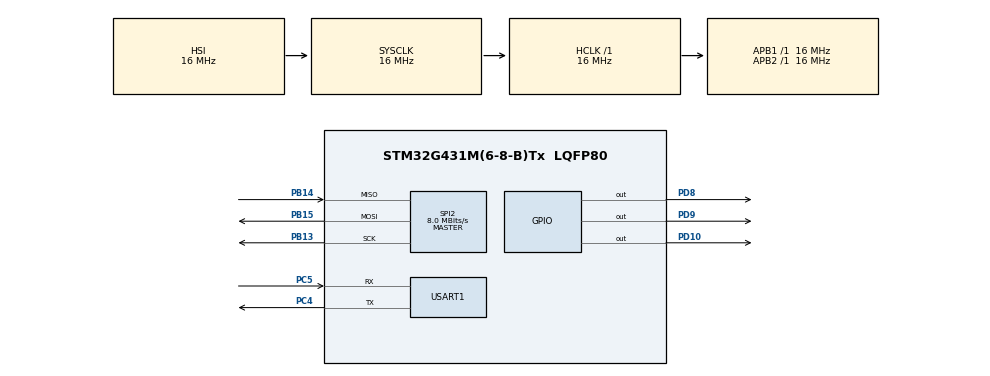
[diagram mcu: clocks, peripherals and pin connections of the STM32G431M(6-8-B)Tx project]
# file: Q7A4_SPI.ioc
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Mcu.Family=STM32G4
Mcu.Name=STM32G431M(6-8-B)Tx
Mcu.Package=LQFP80
NVIC.PriorityGroup=NVIC_PRIORITYGROUP_4
PA13.Mode=Serial_Wire
PA13.Signal=SYS_JTMS-SWDIO
PA14.Mode=Serial_Wire
PA14.Signal=SYS_JTCK-SWCLK
PB13.Mode=Full_Duplex_Master
PB13.Signal=SPI2_SCK
PB14.Mode=Full_Duplex_Master
PB14.Signal=SPI2_MISO
PB15.Mode=Full_Duplex_Master
PB15.Signal=SPI2_MOSI
PC4.Mode=Asynchronous
PC4.Signal=USART1_TX
PC5.Mode=Asynchronous
PC5.Signal=USART1_RX
PD10.Signal=GPIO_Output
PD8.Signal=GPIO_Output
PD9.Signal=GPIO_Output
ProjectManager.HeapSize=0x200
ProjectManager.StackSize=0x400
ProjectManager.TargetToolchain=STM32CubeIDE
RCC.AHBFreq_Value=16000000
RCC.APB1Freq_Value=16000000
RCC.APB1TimFreq_Value=16000000
RCC.APB2Freq_Value=16000000
RCC.APB2TimFreq_Value=16000000
RCC.CortexFreq_Value=16000000
RCC.EXTERNAL_CLOCK_VALUE=12288000
RCC.HCLKFreq_Value=16000000
RCC.HSE_VALUE=8000000
RCC.HSI48_VALUE=48000000
RCC.HSI_VALUE=16000000
RCC.LSE_VALUE=32768
RCC.SYSCLKFreq_VALUE=16000000
RCC.USBFreq_Value=64000000
RCC.VCOOutputFreq_Value=128000000
SPI2.CalculateBaudRate=8.0 MBits/s
SPI2.DataSize=SPI_DATASIZE_8BIT
SPI2.Direction=SPI_DIRECTION_2LINES
SPI2.Mode=SPI_MODE_MASTER
SPI2.VirtualType=VM_MASTER
USART1.VirtualMode-Asynchronous=VM_ASYNC
VP_SYS_VS_DBSignals.Mode=DisableDeadBatterySignals
board=custom

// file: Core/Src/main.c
/* USER CODE BEGIN Header */
/**
  ******************************************************************************
  * @file           : main.c
  * @brief          : Main program body
  ******************************************************************************
  * @attention
  *
  * Copyright (c) 2025 STMicroelectronics.
  * All rights reserved.
  *
  * This software is licensed under terms that can be found in the LICENSE file
  * in the root directory of this software component.
  * If no LICENSE file comes with this software, it is provided AS-IS.
  *
  ******************************************************************************
  */
/* USER CODE END Header */
#include "main.h"
#include "string.h"
#include "stdio.h"

/* USER CODE BEGIN Includes */
#define EEPROM_WREN  0x06 // Write Enable
#define EEPROM_WRITE 0x02 // Write Data
#define EEPROM_RDSR  0x05 // Read Status Register
#define EEPROM_READ  0x03 // Read Data
/* USER CODE END Includes */

SPI_HandleTypeDef hspi2;

UART_HandleTypeDef huart1;

void SystemClock_Config(void);
static void MX_GPIO_Init(void);
static void MX_SPI2_Init(void);
static void MX_USART1_UART_Init(void);

#include "main.h"
#include "string.h"
#include "stdio.h"

/* USER CODE BEGIN Includes */
#define EEPROM_WREN  0x06 // Write Enable
#define EEPROM_WRITE 0x02 // Write Data
#define EEPROM_RDSR  0x05 // Read Status Register
#define EEPROM_READ  0x03 // Read Data
/* USER CODE END Includes */

SPI_HandleTypeDef hspi2;

UART_HandleTypeDef huart1;

void SystemClock_Config(void);
static void MX_GPIO_Init(void);
static void MX_SPI2_Init(void);
static void MX_USART1_UART_Init(void);

int main(void)
{
  /* USER CODE BEGIN 1 */
  HAL_StatusTypeDef status;
  /* USER CODE END 1 */

  /* MCU Configuration--------------------------------------------------------*/

  /* Reset of all peripherals, Initializes the Flash interface and the Systick. */
  HAL_Init();

  /* Configure the system clock */
  SystemClock_Config();

  /* USER CODE BEGIN SysInit */
  // MX_IWDG_Init(); // Disabled to prevent resets
  /* USER CODE END SysInit */

  /* Initialize all configured peripherals */
  MX_GPIO_Init();
  MX_SPI2_Init();
  MX_USART1_UART_Init();
  /* USER CODE BEGIN 2 */
  uint8_t addr[2];
  uint16_t memAddr = 0x100; // EEPROM address
  uint8_t DATA_TO_SPI[8] = {'C', '-', 'D', 'A', 'C', 'B', 'L', 'R'}; // String to write
  uint8_t wip;
  uint8_t spiDataRecv[9]; // 8 bytes + null terminator
  char printBuffer[64];
  uint8_t wren_cmd = EEPROM_WREN;
  uint8_t write_cmd = EEPROM_WRITE;
  uint8_t rdsr_cmd = EEPROM_RDSR;
  uint8_t read_cmd = EEPROM_READ;

  HAL_GPIO_WritePin(GPIOD, GPIO_PIN_9, 1);
  HAL_GPIO_WritePin(GPIOD, GPIO_PIN_10, 1);
  HAL_GPIO_WritePin(GPIOD, GPIO_PIN_8, 1);
  HAL_Delay(500);

  // Send Write Enable command
  HAL_GPIO_WritePin(GPIOD, GPIO_PIN_8, 0);
  status = HAL_SPI_Transmit(&hspi2, (uint8_t*)&wren_cmd, 1, 1000);
  HAL_GPIO_WritePin(GPIOD, GPIO_PIN_8, 1);
  if (status != HAL_OK) {
    HAL_UART_Transmit(&huart1, (const uint8_t*)"Write Enable Failed\n\r", sizeof("Write Enable Failed\n\r"), 1000);
    while (1); // Halt on error
  }
  HAL_UART_Transmit(&huart1, (const uint8_t*)"Write Enabled\n\r", sizeof("Write Enabled\n\r"), 1000);

  // Prepare address
  addr[0] = memAddr >> 8; // High byte
  addr[1] = memAddr;      // Low byte

  // Write data to EEPROM
  HAL_GPIO_WritePin(GPIOD, GPIO_PIN_8, 0);
  status = HAL_SPI_Transmit(&hspi2, (uint8_t*)&write_cmd, 1, 1000);
  if (status == HAL_OK) {
    status = HAL_SPI_Transmit(&hspi2, (uint8_t*)addr, 2, 1000);
  }
  if (status == HAL_OK) {
    status = HAL_SPI_Transmit(&hspi2, (uint8_t*)DATA_TO_SPI, 8, 1000);
  }
  HAL_GPIO_WritePin(GPIOD, GPIO_PIN_8, 1);
  if (status != HAL_OK) {
    HAL_UART_Transmit(&huart1, (const uint8_t*)"Write Failed\n\r", sizeof("Write Failed\n\r"), 1000);
    while (1); // Halt on error
  }
  HAL_UART_Transmit(&huart1, (const uint8_t*)"Written\n\r", sizeof("Written\n\r"), 1000);

  // Poll Write-in-Progress
  wip = 1;
  while (wip)
  {
    HAL_GPIO_WritePin(GPIOD, GPIO_PIN_8, 0);
    status = HAL_SPI_Transmit(&hspi2, (uint8_t*)&rdsr_cmd, 1, 1000);
    if (status == HAL_OK) {
      status = HAL_SPI_Receive(&hspi2, (uint8_t*)&spiDataRecv, 1, 1000);
    }
    HAL_GPIO_WritePin(GPIOD, GPIO_PIN_8, 1);
    if (status != HAL_OK) {
      HAL_UART_Transmit(&huart1, (const uint8_t*)"Status Read Failed\n\r", sizeof("Status Read Failed\n\r"), 1000);
      while (1); // Halt on error
    }
    wip = spiDataRecv[0] & 0x01;
  }

  // Read data from EEPROM
  memset(spiDataRecv, 0, sizeof(spiDataRecv));
  HAL_GPIO_WritePin(GPIOD, GPIO_PIN_8, 0);
  status = HAL_SPI_Transmit(&hspi2, (uint8_t*)&read_cmd, 1, 1000);
  if (status == HAL_OK) {
    status = HAL_SPI_Transmit(&hspi2, (uint8_t*)addr, 2, 1000);
  }
  if (status == HAL_OK) {
    status = HAL_SPI_Receive(&hspi2, (uint8_t*)&spiDataRecv, 8, 1000);
  }
  HAL_GPIO_WritePin(GPIOD, GPIO_PIN_8, 1);
  if (status != HAL_OK) {
    HAL_UART_Transmit(&huart1, (const uint8_t*)"Read Failed\n\r", sizeof("Read Failed\n\r"), 1000);
    while (1); // Halt on error
  }

  spiDataRecv[8] = '\0'; // Null-terminate for string display
  sprintf(printBuffer, "\n\rData Received From addr: 0X%04X is: %s\n\r", memAddr, spiDataRecv);
  HAL_UART_Transmit(&huart1, (uint8_t*)printBuffer, strlen(printBuffer), 1000);

  memset(printBuffer, 0, sizeof(printBuffer));
  memset(spiDataRecv, 0, sizeof(spiDataRecv));
  /* USER CODE END 3 */
  while (1)
  {
    /* Infinite loop to prevent reset */
  }
}

void SystemClock_Config(void)
{
  RCC_OscInitTypeDef RCC_OscInitStruct = {0};
  RCC_ClkInitTypeDef RCC_ClkInitStruct = {0};

  /** Configure the main internal regulator output voltage
  */
  HAL_PWREx_ControlVoltageScaling(PWR_REGULATOR_VOLTAGE_SCALE1);

  /** Initializes the RCC Oscillators according to the specified parameters
  * in the RCC_OscInitTypeDef structure.
  */
  RCC_OscInitStruct.OscillatorType = RCC_OSCILLATORTYPE_HSI;
  RCC_OscInitStruct.HSIState = RCC_HSI_ON;
  RCC_OscInitStruct.HSICalibrationValue = RCC_HSICALIBRATION_DEFAULT;
  RCC_OscInitStruct.PLL.PLLState = RCC_PLL_NONE;
  if (HAL_RCC_OscConfig(&RCC_OscInitStruct) != HAL_OK)
  {
    Error_Handler();
  }

  /** Initializes the CPU, AHB and APB buses clocks
  */
  RCC_ClkInitStruct.ClockType = RCC_CLOCKTYPE_HCLK|RCC_CLOCKTYPE_SYSCLK
                              |RCC_CLOCKTYPE_PCLK1|RCC_CLOCKTYPE_PCLK2;
  RCC_ClkInitStruct.SYSCLKSource = RCC_SYSCLKSOURCE_HSI;
  RCC_ClkInitStruct.AHBCLKDivider = RCC_SYSCLK_DIV1;
  RCC_ClkInitStruct.APB1CLKDivider = RCC_HCLK_DIV1;
  RCC_ClkInitStruct.APB2CLKDivider = RCC_HCLK_DIV1;

  if (HAL_RCC_ClockConfig(&RCC_ClkInitStruct, FLASH_LATENCY_0) != HAL_OK)
  {
    Error_Handler();
  }
}

static void MX_SPI2_Init(void)
{

  /* SPI2 parameter configuration*/
  hspi2.Instance = SPI2;
  hspi2.Init.Mode = SPI_MODE_MASTER;
  hspi2.Init.Direction = SPI_DIRECTION_2LINES;
  hspi2.Init.DataSize = SPI_DATASIZE_8BIT;
  hspi2.Init.CLKPolarity = SPI_POLARITY_LOW;
  hspi2.Init.CLKPhase = SPI_PHASE_1EDGE;
  hspi2.Init.NSS = SPI_NSS_SOFT;
  hspi2.Init.BaudRatePrescaler = SPI_BAUDRATEPRESCALER_2;
  hspi2.Init.FirstBit = SPI_FIRSTBIT_MSB;
  hspi2.Init.TIMode = SPI_TIMODE_DISABLE;
  hspi2.Init.CRCCalculation = SPI_CRCCALCULATION_DISABLE;
  hspi2.Init.CRCPolynomial = 7;
  hspi2.Init.CRCLength = SPI_CRC_LENGTH_DATASIZE;
  hspi2.Init.NSSPMode = SPI_NSS_PULSE_ENABLE;
  if (HAL_SPI_Init(&hspi2) != HAL_OK)
  {
    Error_Handler();
  }

}

static void MX_USART1_UART_Init(void)
{

  huart1.Instance = USART1;
  huart1.Init.BaudRate = 115200;
  huart1.Init.WordLength = UART_WORDLENGTH_8B;
  huart1.Init.StopBits = UART_STOPBITS_1;
  huart1.Init.Parity = UART_PARITY_NONE;
  huart1.Init.Mode = UART_MODE_TX_RX;
  huart1.Init.HwFlowCtl = UART_HWCONTROL_NONE;
  huart1.Init.OverSampling = UART_OVERSAMPLING_16;
  huart1.Init.OneBitSampling = UART_ONE_BIT_SAMPLE_DISABLE;
  huart1.Init.ClockPrescaler = UART_PRESCALER_DIV1;
  huart1.AdvancedInit.AdvFeatureInit = UART_ADVFEATURE_NO_INIT;
  if (HAL_UART_Init(&huart1) != HAL_OK)
  {
    Error_Handler();
  }
  if (HAL_UARTEx_SetTxFifoThreshold(&huart1, UART_TXFIFO_THRESHOLD_1_8) != HAL_OK)
  {
    Error_Handler();
  }
  if (HAL_UARTEx_SetRxFifoThreshold(&huart1, UART_RXFIFO_THRESHOLD_1_8) != HAL_OK)
  {
    Error_Handler();
  }
  if (HAL_UARTEx_DisableFifoMode(&huart1) != HAL_OK)
  {
    Error_Handler();
  }

}

static void MX_GPIO_Init(void)
{
  GPIO_InitTypeDef GPIO_InitStruct = {0};

  /* GPIO Ports Clock Enable */
  __HAL_RCC_GPIOC_CLK_ENABLE();
  __HAL_RCC_GPIOB_CLK_ENABLE();
  __HAL_RCC_GPIOD_CLK_ENABLE();
  __HAL_RCC_GPIOA_CLK_ENABLE();

  /*Configure GPIO pin Output Level */
  HAL_GPIO_WritePin(GPIOD, GPIO_PIN_8|GPIO_PIN_9|GPIO_PIN_10, GPIO_PIN_RESET);

  /*Configure GPIO pins : PD8 PD9 PD10 */
  GPIO_InitStruct.Pin = GPIO_PIN_8|GPIO_PIN_9|GPIO_PIN_10;
  GPIO_InitStruct.Mode = GPIO_MODE_OUTPUT_PP;
  GPIO_InitStruct.Pull = GPIO_NOPULL;
  GPIO_InitStruct.Speed = GPIO_SPEED_FREQ_LOW;
  HAL_GPIO_Init(GPIOD, &GPIO_InitStruct);

}

void Error_Handler(void)
{
  __disable_irq();
  while (1)
  {
  }
}
